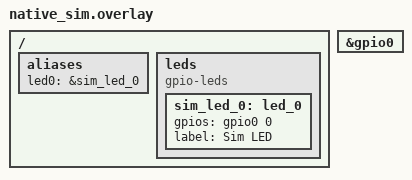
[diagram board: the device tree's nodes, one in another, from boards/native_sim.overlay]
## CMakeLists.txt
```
cmake_minimum_required(VERSION 3.20.0)

# Allow per-board overlays in app/boards/<board>.overlay
list(APPEND DTS_EXTRA_OVERLAYS ${CMAKE_CURRENT_SOURCE_DIR}/boards)

find_package(Zephyr REQUIRED HINTS $ENV{ZEPHYR_BASE})

project(nrf_connect_starter LANGUAGES C)

target_sources(app PRIVATE
    src/main.c
    src/blinker.c
)

target_include_directories(app PRIVATE include)
```

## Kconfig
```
mainmenu "NRF Connect Starter"

source "Kconfig.zephyr"

config STARTER_BLINK_INTERVAL_MS
	int "LED blink interval (ms)"
	default 500
	help
	  How fast LED0 toggles.
```

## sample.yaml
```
sample:
  description: NRF Connect starter sample - blinking LED with logging.
  name: nrf-connect-starter

common:
  integration_platforms:
    - nrf52840dk/nrf52840
    - nrf52833dk/nrf52833
    - nrf5340dk/nrf5340/cpuapp
    - native_sim
  tags:
    - gpio
    - led
    - starter

tests:
  sample.starter.blink:
    harness: console
    harness_config:
      type: one_line
      regex:
        - "blinker started"
```

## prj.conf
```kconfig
# Default Kconfig — overridden by board-specific files in boards/<board>.conf

# Console & logging
CONFIG_LOG=y
CONFIG_LOG_MODE_DEFERRED=y
CONFIG_LOG_BUFFER_SIZE=2048
CONFIG_LOG_DEFAULT_LEVEL=3
CONFIG_PRINTK=y

# GPIO
CONFIG_GPIO=y

# Power management
CONFIG_PM=y
CONFIG_PM_DEVICE=y

# Useful kernel features
CONFIG_THREAD_NAME=y
CONFIG_THREAD_RUNTIME_STATS=y
CONFIG_THREAD_ANALYZER=y
CONFIG_THREAD_ANALYZER_USE_LOG=y
CONFIG_THREAD_ANALYZER_AUTO=n

# Reboot on fault, hand off to debugger if attached
CONFIG_RESET_ON_FATAL_ERROR=y

# Library configuration
CONFIG_NEWLIB_LIBC=y

# Optional: enable for wireless work in your project
# CONFIG_BT=y
# CONFIG_BT_PERIPHERAL=y
# CONFIG_BT_DEVICE_NAME="ncs-starter"
```

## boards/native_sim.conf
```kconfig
CONFIG_GPIO_EMUL=y
CONFIG_LOG_BACKEND_NATIVE_POSIX=y
CONFIG_RESET_ON_FATAL_ERROR=n
```

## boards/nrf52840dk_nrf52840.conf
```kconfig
# nRF52840 DK-specific overrides go here.
# Default board config in prj.conf is fine for blinker.
```

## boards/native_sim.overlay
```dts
/* native_sim doesn't have GPIO pins; alias led0 to a soft "led" via the
 * gpio_emul controller so the build (and Twister) works without hardware. */
/ {
	aliases {
		led0 = &sim_led_0;
	};

	leds {
		compatible = "gpio-leds";
		sim_led_0: led_0 {
			gpios = <&gpio0 0 GPIO_ACTIVE_HIGH>;
			label = "Sim LED";
		};
	};
};

&gpio0 {
	status = "okay";
};
```

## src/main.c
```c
#include "blinker.h"

#include <zephyr/device.h>
#include <zephyr/kernel.h>
#include <zephyr/logging/log.h>

LOG_MODULE_REGISTER(main, CONFIG_LOG_DEFAULT_LEVEL);

int main(void)
{
	int ret;

	LOG_INF("nrf-connect-starter booting on %s", CONFIG_BOARD);

	ret = blinker_init();
	if (ret < 0) {
		LOG_ERR("blinker init failed: %d", ret);
		return ret;
	}

	while (1) {
		k_sleep(K_FOREVER);
	}

	return 0;
}
```

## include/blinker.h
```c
#pragma once

#include <stdbool.h>
#include <stdint.h>

/**
 * @brief Initialise the blinker module.
 *
 * Looks up the board's `led0` alias from devicetree, configures it as an
 * output, and starts a kernel work item that toggles it on the configured
 * interval.
 *
 * @return 0 on success, negative errno on failure.
 */
int blinker_init(void);

/**
 * @brief Pause/resume the blinker.
 */
void blinker_set_enabled(bool enabled);

/**
 * @brief Whether the blinker is currently active.
 */
bool blinker_is_enabled(void);
```

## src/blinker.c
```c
#include "blinker.h"

#include <zephyr/device.h>
#include <zephyr/devicetree.h>
#include <zephyr/drivers/gpio.h>
#include <zephyr/kernel.h>
#include <zephyr/logging/log.h>

LOG_MODULE_REGISTER(blinker, CONFIG_LOG_DEFAULT_LEVEL);

#define LED0_NODE DT_ALIAS(led0)

#if !DT_NODE_HAS_STATUS(LED0_NODE, okay)
#error "Board missing led0 alias in devicetree — add a boards/<board>.overlay"
#endif

static const struct gpio_dt_spec led = GPIO_DT_SPEC_GET(LED0_NODE, gpios);

static struct k_work_delayable work;
static atomic_t enabled = ATOMIC_INIT(1);
static bool led_state;

static void blink_handler(struct k_work *unused)
{
	ARG_UNUSED(unused);

	if (atomic_get(&enabled)) {
		led_state = !led_state;
		gpio_pin_set_dt(&led, led_state);
	}

	k_work_schedule(&work, K_MSEC(CONFIG_STARTER_BLINK_INTERVAL_MS));
}

int blinker_init(void)
{
	int ret;

	if (!gpio_is_ready_dt(&led)) {
		LOG_ERR("led0 gpio not ready");
		return -ENODEV;
	}

	ret = gpio_pin_configure_dt(&led, GPIO_OUTPUT_INACTIVE);
	if (ret < 0) {
		LOG_ERR("failed to configure led0 (%d)", ret);
		return ret;
	}

	k_work_init_delayable(&work, blink_handler);
	k_work_schedule(&work, K_MSEC(CONFIG_STARTER_BLINK_INTERVAL_MS));

	LOG_INF("blinker started @ %d ms", CONFIG_STARTER_BLINK_INTERVAL_MS);
	return 0;
}

void blinker_set_enabled(bool enable)
{
	atomic_set(&enabled, enable ? 1 : 0);
	if (!enable) {
		gpio_pin_set_dt(&led, 0);
		led_state = false;
	}
	LOG_INF("blinker %s", enable ? "resumed" : "paused");
}

bool blinker_is_enabled(void)
{
	return atomic_get(&enabled) != 0;
}
```
